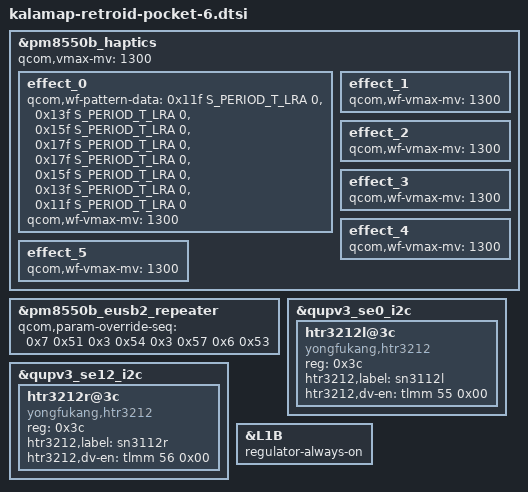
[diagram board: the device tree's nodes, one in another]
#include "kalamap-moorechip-common.dtsi"

&pm8550b_haptics {
	effect_0 {
		/* CLICK */
		qcom,wf-pattern-data =  <0x11f  S_PERIOD_T_LRA  0>,
					<0x13f  S_PERIOD_T_LRA  0>,
					<0x15f  S_PERIOD_T_LRA  0>,
					<0x17f  S_PERIOD_T_LRA  0>,
					<0x17f  S_PERIOD_T_LRA  0>,
					<0x15f  S_PERIOD_T_LRA  0>,
					<0x13f  S_PERIOD_T_LRA  0>,
					<0x11f  S_PERIOD_T_LRA  0>;
		/delete-property/ qcom,wf-pattern-preload;
	};
};

&pm8550b_eusb2_repeater {
	qcom,param-override-seq =
		/* <value reg_offset> */
		/* Adjust HS trasmit amplitude */
		<0x7 0x51
		/* Squelch detection threshold */
		 0x3 0x54
		/* Tx pre-emphasis tuning */
		 0x3 0x57
		/* HS disconnect threshold */
		 0x6 0x53>;
};

&pm8550b_haptics {
	/delete-property/ qcom,use-erm;
	qcom,vmax-mv = <1300>;

	effect_0 {
		/* CLICK */
		qcom,wf-vmax-mv = <1300>;
	};

	effect_1 {
		/* DOUBLE_CLICK */
		qcom,wf-vmax-mv = <1300>;
	};

	effect_2 {
		/* TICK */
		qcom,wf-vmax-mv = <1300>;
	};

	effect_3 {
		/* THUD */
		qcom,wf-vmax-mv = <1300>;
	};

	effect_4 {
		/* POP */
		qcom,wf-vmax-mv = <1300>;
	};

	effect_5 {
		/* HEAVY CLICK */
		qcom,wf-vmax-mv = <1300>;
	};
};

&qupv3_se0_i2c {
	#address-cells = <1>;
	#size-cells = <0>;
	status = "ok";

	htr3212l@3c {
		compatible = "yongfukang,htr3212";
		reg = <0x3c>;
		htr3212,label = "sn3112l";
		htr3212,dv-en = <&tlmm 55 0x00>;
	};
};

&qupv3_se12_i2c {
	#address-cells = <1>;
	#size-cells = <0>;
	status = "ok";

	htr3212r@3c {
		compatible = "yongfukang,htr3212";
		reg = <0x3c>;
		htr3212,label = "sn3112r";
		htr3212,dv-en = <&tlmm 56 0x00>;
	};
};

// TODO: ???
&L1B {
	regulator-always-on;
};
